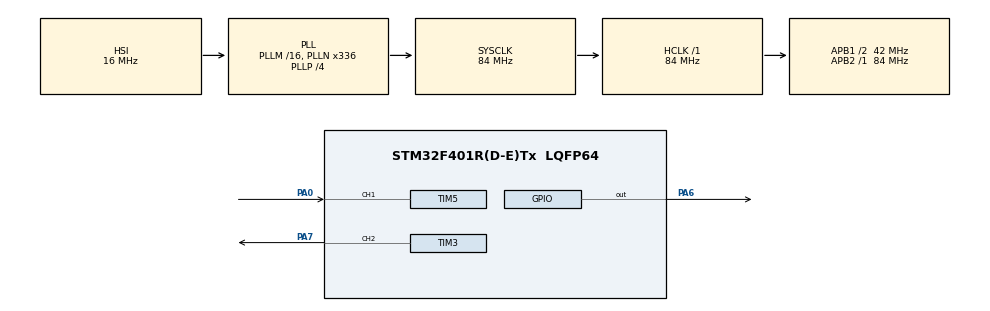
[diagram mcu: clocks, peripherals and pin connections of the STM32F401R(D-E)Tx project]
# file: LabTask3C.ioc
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Mcu.Family=STM32F4
Mcu.Name=STM32F401R(D-E)Tx
Mcu.Package=LQFP64
NVIC.PriorityGroup=NVIC_PRIORITYGROUP_4
NVIC.TIM2_IRQn=true\:0\:0\:false\:false\:true\:true\:true\:true
NVIC.TIM3_IRQn=true\:0\:0\:false\:false\:true\:true\:true\:true
NVIC.TIM5_IRQn=true\:0\:0\:false\:false\:true\:true\:true\:true
PA0-WKUP.Signal=S_TIM5_CH1
PA6.Signal=GPIO_Output
PA7.Signal=S_TIM3_CH2
ProjectManager.HeapSize=0x200
ProjectManager.StackSize=0x400
ProjectManager.TargetToolchain=STM32CubeIDE
RCC.48MHZClocksFreq_Value=84000000
RCC.AHBFreq_Value=84000000
RCC.APB1CLKDivider=RCC_HCLK_DIV2
RCC.APB1Freq_Value=42000000
RCC.APB1TimFreq_Value=84000000
RCC.APB2Freq_Value=84000000
RCC.APB2TimFreq_Value=84000000
RCC.CortexFreq_Value=84000000
RCC.HCLKFreq_Value=84000000
RCC.HSE_VALUE=25000000
RCC.HSI_VALUE=16000000
RCC.LSE_VALUE=32768
RCC.PLLN=336
RCC.PLLP=RCC_PLLP_DIV4
RCC.SYSCLKFreq_VALUE=84000000
RCC.SYSCLKSource=RCC_SYSCLKSOURCE_PLLCLK
RCC.VCOOutputFreq_Value=336000000
SH.S_TIM3_CH2.0=TIM3_CH2,PWM Generation2 CH2
SH.S_TIM5_CH1.0=TIM5_CH1,Input_Capture1_from_TI1
TIM2.Period=49
TIM2.Prescaler=83
TIM3.Channel-PWM\ Generation2\ CH2=TIM_CHANNEL_2
TIM3.Period=99
TIM3.Prescaler=83
TIM3.Pulse-PWM\ Generation2\ CH2=50
TIM5.Channel-Input_Capture1_from_TI1=TIM_CHANNEL_1
TIM5.Channel-Input_Capture2_from_TI1_63=TIM_CHANNEL_2
TIM5.ICPolarity_CH2=TIM_INPUTCHANNELPOLARITY_FALLING
VP_TIM2_VS_ClockSourceINT.Mode=Internal
VP_TIM3_VS_ClockSourceINT.Mode=Internal
VP_TIM5_VS_ClockSourceINT.Mode=Internal
VP_TIM5_VS_indirect_ch1.Mode=Input_Capture2_from_TI1_63
board=custom

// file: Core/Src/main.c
/* USER CODE BEGIN Header */
/**
  ******************************************************************************
  * @file           : main.c
  * @brief          : Main program body
  ******************************************************************************
  * @attention
  *
  * Copyright (c) 2026 STMicroelectronics.
  * All rights reserved.
  *
  * This software is licensed under terms that can be found in the LICENSE file
  * in the root directory of this software component.
  * If no LICENSE file comes with this software, it is provided AS-IS.
  *
  ******************************************************************************
  */
/* USER CODE END Header */
#include "main.h"

TIM_HandleTypeDef htim2;
TIM_HandleTypeDef htim3;
TIM_HandleTypeDef htim5;

/* USER CODE BEGIN PV */
#define CAPTURE_COUNT 1000

volatile uint32_t rising_times[CAPTURE_COUNT];
volatile uint32_t falling_times[CAPTURE_COUNT];

volatile uint32_t rising_count = 0;
volatile uint32_t falling_count = 0;
volatile uint8_t capture_done = 0;
/* USER CODE END PV */

void SystemClock_Config(void);
static void MX_GPIO_Init(void);
static void MX_TIM3_Init(void);
static void MX_TIM2_Init(void);
static void MX_TIM5_Init(void);

int main(void)
{

  /* MCU Configuration--------------------------------------------------------*/

  /* Reset of all peripherals, Initializes the Flash interface and the Systick. */
  HAL_Init();

  /* Configure the system clock */
  SystemClock_Config();

  /* Initialize all configured peripherals */
  MX_GPIO_Init();
  MX_TIM3_Init();
  MX_TIM2_Init();
  MX_TIM5_Init();
  /* USER CODE BEGIN 2 */
  HAL_TIM_IC_Start_IT(&htim5, TIM_CHANNEL_1);
  HAL_TIM_IC_Start_IT(&htim5, TIM_CHANNEL_2);

//  HAL_TIM_PWM_Start(&htim3, TIM_CHANNEL_2);
  HAL_TIM_Base_Start_IT(&htim2);
  /* USER CODE END 2 */

  /* Infinite loop */
  while (1)
  {

  }
}

void SystemClock_Config(void)
{
  RCC_OscInitTypeDef RCC_OscInitStruct = {0};
  RCC_ClkInitTypeDef RCC_ClkInitStruct = {0};

  /** Configure the main internal regulator output voltage
  */
  __HAL_RCC_PWR_CLK_ENABLE();
  __HAL_PWR_VOLTAGESCALING_CONFIG(PWR_REGULATOR_VOLTAGE_SCALE2);

  /** Initializes the RCC Oscillators according to the specified parameters
  * in the RCC_OscInitTypeDef structure.
  */
  RCC_OscInitStruct.OscillatorType = RCC_OSCILLATORTYPE_HSI;
  RCC_OscInitStruct.HSIState = RCC_HSI_ON;
  RCC_OscInitStruct.HSICalibrationValue = RCC_HSICALIBRATION_DEFAULT;
  RCC_OscInitStruct.PLL.PLLState = RCC_PLL_ON;
  RCC_OscInitStruct.PLL.PLLSource = RCC_PLLSOURCE_HSI;
  RCC_OscInitStruct.PLL.PLLM = 16;
  RCC_OscInitStruct.PLL.PLLN = 336;
  RCC_OscInitStruct.PLL.PLLP = RCC_PLLP_DIV4;
  RCC_OscInitStruct.PLL.PLLQ = 4;
  if (HAL_RCC_OscConfig(&RCC_OscInitStruct) != HAL_OK)
  {
    Error_Handler();
  }

  /** Initializes the CPU, AHB and APB buses clocks
  */
  RCC_ClkInitStruct.ClockType = RCC_CLOCKTYPE_HCLK|RCC_CLOCKTYPE_SYSCLK
                              |RCC_CLOCKTYPE_PCLK1|RCC_CLOCKTYPE_PCLK2;
  RCC_ClkInitStruct.SYSCLKSource = RCC_SYSCLKSOURCE_PLLCLK;
  RCC_ClkInitStruct.AHBCLKDivider = RCC_SYSCLK_DIV1;
  RCC_ClkInitStruct.APB1CLKDivider = RCC_HCLK_DIV2;
  RCC_ClkInitStruct.APB2CLKDivider = RCC_HCLK_DIV1;

  if (HAL_RCC_ClockConfig(&RCC_ClkInitStruct, FLASH_LATENCY_2) != HAL_OK)
  {
    Error_Handler();
  }
}

static void MX_TIM2_Init(void)
{

  TIM_ClockConfigTypeDef sClockSourceConfig = {0};
  TIM_MasterConfigTypeDef sMasterConfig = {0};

  htim2.Instance = TIM2;
  htim2.Init.Prescaler = 83;
  htim2.Init.CounterMode = TIM_COUNTERMODE_UP;
  htim2.Init.Period = 49;
  htim2.Init.ClockDivision = TIM_CLOCKDIVISION_DIV1;
  htim2.Init.AutoReloadPreload = TIM_AUTORELOAD_PRELOAD_DISABLE;
  if (HAL_TIM_Base_Init(&htim2) != HAL_OK)
  {
    Error_Handler();
  }
  sClockSourceConfig.ClockSource = TIM_CLOCKSOURCE_INTERNAL;
  if (HAL_TIM_ConfigClockSource(&htim2, &sClockSourceConfig) != HAL_OK)
  {
    Error_Handler();
  }
  sMasterConfig.MasterOutputTrigger = TIM_TRGO_RESET;
  sMasterConfig.MasterSlaveMode = TIM_MASTERSLAVEMODE_DISABLE;
  if (HAL_TIMEx_MasterConfigSynchronization(&htim2, &sMasterConfig) != HAL_OK)
  {
    Error_Handler();
  }

}

static void MX_TIM3_Init(void)
{

  TIM_ClockConfigTypeDef sClockSourceConfig = {0};
  TIM_MasterConfigTypeDef sMasterConfig = {0};
  TIM_OC_InitTypeDef sConfigOC = {0};

  htim3.Instance = TIM3;
  htim3.Init.Prescaler = 83;
  htim3.Init.CounterMode = TIM_COUNTERMODE_UP;
  htim3.Init.Period = 99;
  htim3.Init.ClockDivision = TIM_CLOCKDIVISION_DIV1;
  htim3.Init.AutoReloadPreload = TIM_AUTORELOAD_PRELOAD_DISABLE;
  if (HAL_TIM_Base_Init(&htim3) != HAL_OK)
  {
    Error_Handler();
  }
  sClockSourceConfig.ClockSource = TIM_CLOCKSOURCE_INTERNAL;
  if (HAL_TIM_ConfigClockSource(&htim3, &sClockSourceConfig) != HAL_OK)
  {
    Error_Handler();
  }
  if (HAL_TIM_PWM_Init(&htim3) != HAL_OK)
  {
    Error_Handler();
  }
  sMasterConfig.MasterOutputTrigger = TIM_TRGO_RESET;
  sMasterConfig.MasterSlaveMode = TIM_MASTERSLAVEMODE_DISABLE;
  if (HAL_TIMEx_MasterConfigSynchronization(&htim3, &sMasterConfig) != HAL_OK)
  {
    Error_Handler();
  }
  sConfigOC.OCMode = TIM_OCMODE_PWM1;
  sConfigOC.Pulse = 50;
  sConfigOC.OCPolarity = TIM_OCPOLARITY_HIGH;
  sConfigOC.OCFastMode = TIM_OCFAST_DISABLE;
  if (HAL_TIM_PWM_ConfigChannel(&htim3, &sConfigOC, TIM_CHANNEL_2) != HAL_OK)
  {
    Error_Handler();
  }
  HAL_TIM_MspPostInit(&htim3);

}

static void MX_TIM5_Init(void)
{

  TIM_ClockConfigTypeDef sClockSourceConfig = {0};
  TIM_MasterConfigTypeDef sMasterConfig = {0};
  TIM_IC_InitTypeDef sConfigIC = {0};

  htim5.Instance = TIM5;
  htim5.Init.Prescaler = 0;
  htim5.Init.CounterMode = TIM_COUNTERMODE_UP;
  htim5.Init.Period = 4294967295;
  htim5.Init.ClockDivision = TIM_CLOCKDIVISION_DIV1;
  htim5.Init.AutoReloadPreload = TIM_AUTORELOAD_PRELOAD_DISABLE;
  if (HAL_TIM_Base_Init(&htim5) != HAL_OK)
  {
    Error_Handler();
  }
  sClockSourceConfig.ClockSource = TIM_CLOCKSOURCE_INTERNAL;
  if (HAL_TIM_ConfigClockSource(&htim5, &sClockSourceConfig) != HAL_OK)
  {
    Error_Handler();
  }
  if (HAL_TIM_IC_Init(&htim5) != HAL_OK)
  {
    Error_Handler();
  }
  sMasterConfig.MasterOutputTrigger = TIM_TRGO_RESET;
  sMasterConfig.MasterSlaveMode = TIM_MASTERSLAVEMODE_DISABLE;
  if (HAL_TIMEx_MasterConfigSynchronization(&htim5, &sMasterConfig) != HAL_OK)
  {
    Error_Handler();
  }
  sConfigIC.ICPolarity = TIM_INPUTCHANNELPOLARITY_RISING;
  sConfigIC.ICSelection = TIM_ICSELECTION_DIRECTTI;
  sConfigIC.ICPrescaler = TIM_ICPSC_DIV1;
  sConfigIC.ICFilter = 0;
  if (HAL_TIM_IC_ConfigChannel(&htim5, &sConfigIC, TIM_CHANNEL_1) != HAL_OK)
  {
    Error_Handler();
  }
  sConfigIC.ICPolarity = TIM_INPUTCHANNELPOLARITY_FALLING;
  sConfigIC.ICSelection = TIM_ICSELECTION_INDIRECTTI;
  if (HAL_TIM_IC_ConfigChannel(&htim5, &sConfigIC, TIM_CHANNEL_2) != HAL_OK)
  {
    Error_Handler();
  }

}

static void MX_GPIO_Init(void)
{
  GPIO_InitTypeDef GPIO_InitStruct = {0};

  /* GPIO Ports Clock Enable */
  __HAL_RCC_GPIOA_CLK_ENABLE();

  /*Configure GPIO pin Output Level */
  HAL_GPIO_WritePin(GPIOA, GPIO_PIN_6, GPIO_PIN_RESET);

  /*Configure GPIO pin : PA6 */
  GPIO_InitStruct.Pin = GPIO_PIN_6;
  GPIO_InitStruct.Mode = GPIO_MODE_OUTPUT_PP;
  GPIO_InitStruct.Pull = GPIO_NOPULL;
  GPIO_InitStruct.Speed = GPIO_SPEED_FREQ_LOW;
  HAL_GPIO_Init(GPIOA, &GPIO_InitStruct);

}

/* USER CODE BEGIN 4 */
void HAL_TIM_PeriodElapsedCallback(TIM_HandleTypeDef *htim)
{
    if (htim->Instance == TIM2)
    {
        HAL_GPIO_TogglePin(GPIOA, GPIO_PIN_6);
    }
}

/* USER CODE BEGIN 4 */

void HAL_TIM_IC_CaptureCallback(TIM_HandleTypeDef *htim)
{
    if (htim->Instance == TIM5 && !capture_done)
    {
        if (htim->Channel == HAL_TIM_ACTIVE_CHANNEL_1)
        {
            if (rising_count < CAPTURE_COUNT)
            {
                rising_times[rising_count++] =
                    HAL_TIM_ReadCapturedValue(htim, TIM_CHANNEL_1);

                if (rising_count >= CAPTURE_COUNT)
                {
                    capture_done = 1;
                    HAL_TIM_IC_Stop_IT(&htim5, TIM_CHANNEL_1);
                    HAL_TIM_IC_Stop_IT(&htim5, TIM_CHANNEL_2);
                }
            }
        }
        else if (htim->Channel == HAL_TIM_ACTIVE_CHANNEL_2)
        {
            if (falling_count < CAPTURE_COUNT)
            {
                falling_times[falling_count++] =
                    HAL_TIM_ReadCapturedValue(htim, TIM_CHANNEL_2);
            }
        }
    }
}

/* USER CODE END 4 */
/* USER CODE END 4 */

void Error_Handler(void)
{
  __disable_irq();
  while (1)
  {
  }
}
